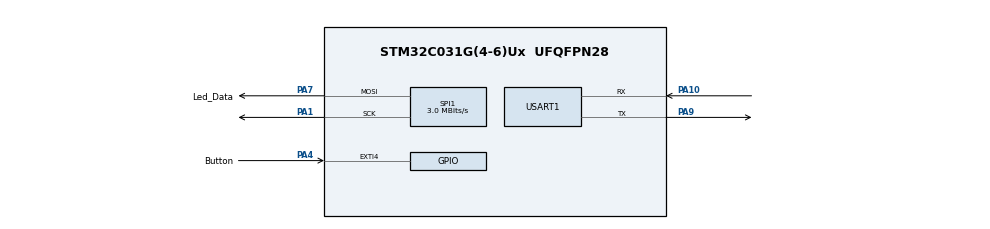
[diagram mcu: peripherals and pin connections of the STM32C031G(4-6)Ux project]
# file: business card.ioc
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Dma.Request0=SPI1_TX
Dma.SPI1_TX.0.Direction=DMA_MEMORY_TO_PERIPH
Dma.SPI1_TX.0.EventEnable=DISABLE
Dma.SPI1_TX.0.Instance=DMA1_Channel1
Dma.SPI1_TX.0.MemDataAlignment=DMA_MDATAALIGN_BYTE
Dma.SPI1_TX.0.MemInc=DMA_MINC_ENABLE
Dma.SPI1_TX.0.Mode=DMA_NORMAL
Dma.SPI1_TX.0.PeriphDataAlignment=DMA_PDATAALIGN_BYTE
Dma.SPI1_TX.0.PeriphInc=DMA_PINC_DISABLE
Dma.SPI1_TX.0.Polarity=HAL_DMAMUX_REQ_GEN_RISING
Dma.SPI1_TX.0.Priority=DMA_PRIORITY_HIGH
Dma.SPI1_TX.0.RequestNumber=1
Dma.SPI1_TX.0.SignalID=NONE
Dma.SPI1_TX.0.SyncEnable=DISABLE
Dma.SPI1_TX.0.SyncPolarity=HAL_DMAMUX_SYNC_NO_EVENT
Dma.SPI1_TX.0.SyncRequestNumber=1
Dma.SPI1_TX.0.SyncSignalID=NONE
Mcu.Family=STM32C0
Mcu.Name=STM32C031G(4-6)Ux
Mcu.Package=UFQFPN28
NVIC.DMA1_Channel1_IRQn=true\:1\:0\:true\:false\:true\:false\:true\:true
NVIC.EXTI4_15_IRQn=true\:2\:0\:true\:false\:true\:true\:true\:true
PA1.Mode=TX_Only_Simplex_Unidirect_Master
PA1.Signal=SPI1_SCK
PA10\ [PA12].Mode=Asynchronous
PA10\ [PA12].Signal=USART1_RX
PA13.Mode=Serial_Wire
PA13.Signal=DEBUG_SWDIO
PA14-BOOT0.Mode=Serial_Wire
PA14-BOOT0.Signal=DEBUG_SWCLK
PA4.GPIO_Label=Button
PA4.GPIO_ModeDefaultEXTI=GPIO_MODE_IT_FALLING
PA4.Signal=GPXTI4
PA7.GPIO_Label=Led_Data
PA7.GPIO_Mode=GPIO_MODE_AF_PP
PA7.GPIO_PuPd=GPIO_NOPULL
PA7.GPIO_Speed=GPIO_SPEED_FREQ_VERY_HIGH
PA7.Mode=TX_Only_Simplex_Unidirect_Master
PA7.PinState=GPIO_PIN_RESET
PA7.Signal=SPI1_MOSI
PA9\ [PA11].Mode=Asynchronous
PA9\ [PA11].Signal=USART1_TX
ProjectManager.HeapSize=0x200
ProjectManager.StackSize=0x400
ProjectManager.TargetToolchain=STM32CubeIDE
RCC.ADCFreq_Value=48000000
RCC.AHBFreq_Value=48000000
RCC.CortexFreq_Value=48000000
RCC.EXTERNAL_CLOCK_VALUE=12288000
RCC.HCLKFreq_Value=48000000
RCC.HSE_VALUE=8000000
RCC.HSISYSCLKDivider=RCC_HSI_DIV1
RCC.HSI_VALUE=48000000
RCC.LSE_VALUE=32768
RCC.SYSCLKFreq_VALUE=48000000
SPI1.BaudRatePrescaler=SPI_BAUDRATEPRESCALER_16
SPI1.CalculateBaudRate=3.0 MBits/s
SPI1.Direction=SPI_DIRECTION_2LINES
SPI1.Mode=SPI_MODE_MASTER
SPI1.NSSPMode=SPI_NSS_PULSE_DISABLE
SPI1.VirtualType=VM_MASTER
USART1.VirtualMode-Asynchronous=VM_ASYNC
VP_SYS_VS_PINREMAP.Mode=PINREMAP
VP_SYS_VS_PINREMAP_10_12.Mode=PINREMAP_10_12
board=custom

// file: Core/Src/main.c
/* USER CODE BEGIN Header */
/**
  ******************************************************************************
  * @file           : main.c
  * @brief          : Main program body
  ******************************************************************************
  * @attention
  *
  * Copyright (c) 2026 STMicroelectronics.
  * All rights reserved.
  *
  * This software is licensed under terms that can be found in the LICENSE file
  * in the root directory of this software component.
  * If no LICENSE file comes with this software, it is provided AS-IS.
  *
  ******************************************************************************
  */
/* USER CODE END Header */
#include "main.h"
#include "dma.h"
#include "spi.h"
#include "usart.h"
#include "gpio.h"

/* USER CODE BEGIN Includes */
#include "led.h"
#include "game.h"
/* USER CODE END Includes */

void SystemClock_Config(void);

int main(void)
{

  /* MCU Configuration--------------------------------------------------------*/

  /* Reset of all peripherals, Initializes the Flash interface and the Systick. */
  HAL_Init();

  /* Configure the system clock */
  SystemClock_Config();

  /* Initialize all configured peripherals */
  MX_GPIO_Init();
  MX_DMA_Init();
  MX_SPI1_Init();
  MX_USART1_UART_Init();
  /* USER CODE BEGIN 2 */

  LED_Init();
  Game_Init();

  /* USER CODE END 2 */

  /* Infinite loop */
  /* USER CODE BEGIN WHILE */
  while (1)
  {

	  Game_Task();
	  __WFI();

    /* USER CODE END WHILE */

  }
}

void SystemClock_Config(void)
{
  RCC_OscInitTypeDef RCC_OscInitStruct = {0};
  RCC_ClkInitTypeDef RCC_ClkInitStruct = {0};

  __HAL_FLASH_SET_LATENCY(FLASH_LATENCY_1);

  /** Initializes the RCC Oscillators according to the specified parameters
  * in the RCC_OscInitTypeDef structure.
  */
  RCC_OscInitStruct.OscillatorType = RCC_OSCILLATORTYPE_HSI;
  RCC_OscInitStruct.HSIState = RCC_HSI_ON;
  RCC_OscInitStruct.HSIDiv = RCC_HSI_DIV1;
  RCC_OscInitStruct.HSICalibrationValue = RCC_HSICALIBRATION_DEFAULT;
  if (HAL_RCC_OscConfig(&RCC_OscInitStruct) != HAL_OK)
  {
    Error_Handler();
  }

  /** Initializes the CPU, AHB and APB buses clocks
  */
  RCC_ClkInitStruct.ClockType = RCC_CLOCKTYPE_HCLK|RCC_CLOCKTYPE_SYSCLK
                              |RCC_CLOCKTYPE_PCLK1;
  RCC_ClkInitStruct.SYSCLKSource = RCC_SYSCLKSOURCE_HSI;
  RCC_ClkInitStruct.SYSCLKDivider = RCC_SYSCLK_DIV1;
  RCC_ClkInitStruct.AHBCLKDivider = RCC_HCLK_DIV1;
  RCC_ClkInitStruct.APB1CLKDivider = RCC_APB1_DIV1;

  if (HAL_RCC_ClockConfig(&RCC_ClkInitStruct, FLASH_LATENCY_1) != HAL_OK)
  {
    Error_Handler();
  }
}

/* USER CODE BEGIN 4 */

/**
  * @brief Forward falling-edge button interrupts to the game input queue.
  * @param GPIO_Pin Pin mask supplied by the HAL EXTI dispatcher.
  */
void HAL_GPIO_EXTI_Falling_Callback(uint16_t GPIO_Pin)
{
  /* Ignore unrelated EXTI sources that may share the callback. */
  if (GPIO_Pin == Button_Pin)
  {
    Game_ButtonPressed();
  }
}

/* USER CODE END 4 */

void Error_Handler(void)
{
  __disable_irq();
  while (1)
  {
  }
}
